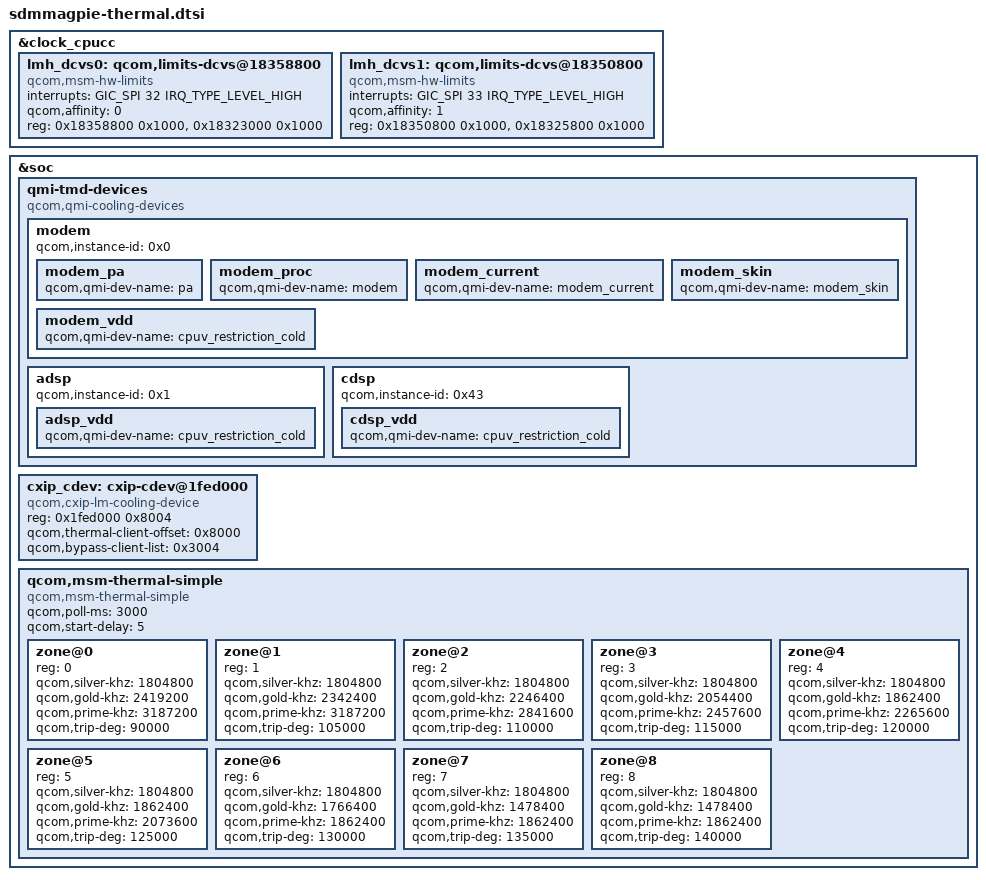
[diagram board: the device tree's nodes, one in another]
/*
 * Copyright (c) 2018-2019, The Linux Foundation. All rights reserved.
 *
 * This program is free software; you can redistribute it and/or modify
 * it under the terms of the GNU General Public License version 2 and
 * only version 2 as published by the Free Software Foundation.
 *
 * This program is distributed in the hope that it will be useful,
 * but WITHOUT ANY WARRANTY; without even the implied warranty of
 * MERCHANTABILITY or FITNESS FOR A PARTICULAR PURPOSE.  See the
 * GNU General Public License for more details.
 */

#include <dt-bindings/thermal/thermal.h>

&clock_cpucc {
	#address-cells = <1>;
	#size-cells = <1>;
	lmh_dcvs0: qcom,limits-dcvs@18358800 {
		compatible = "qcom,msm-hw-limits";
		interrupts = <GIC_SPI 32 IRQ_TYPE_LEVEL_HIGH>;
		qcom,affinity = <0>;
		reg = <0x18358800 0x1000>,
			<0x18323000 0x1000>;
		#thermal-sensor-cells = <0>;
	};

	lmh_dcvs1: qcom,limits-dcvs@18350800 {
		compatible = "qcom,msm-hw-limits";
		interrupts = <GIC_SPI 33 IRQ_TYPE_LEVEL_HIGH>;
		qcom,affinity = <1>;
		reg = <0x18350800 0x1000>,
			<0x18325800 0x1000>;
		#thermal-sensor-cells = <0>;
	};
};

&soc {
	qmi-tmd-devices {
		compatible = "qcom,qmi-cooling-devices";

		modem {
			qcom,instance-id = <0x0>;

			modem_pa: modem_pa {
				qcom,qmi-dev-name = "pa";
				#cooling-cells = <2>;
			};

			modem_proc: modem_proc {
				qcom,qmi-dev-name = "modem";
				#cooling-cells = <2>;
			};

			modem_current: modem_current {
				qcom,qmi-dev-name = "modem_current";
				#cooling-cells = <2>;
			};

			modem_skin: modem_skin {
				qcom,qmi-dev-name = "modem_skin";
				#cooling-cells = <2>;
			};

			modem_vdd: modem_vdd {
				qcom,qmi-dev-name = "cpuv_restriction_cold";
				#cooling-cells = <2>;
			};
		};

		adsp {
			qcom,instance-id = <0x1>;

			adsp_vdd: adsp_vdd {
				qcom,qmi-dev-name = "cpuv_restriction_cold";
				#cooling-cells = <2>;
			};
		};

		cdsp {
			qcom,instance-id = <0x43>;

			cdsp_vdd: cdsp_vdd {
				qcom,qmi-dev-name = "cpuv_restriction_cold";
				#cooling-cells = <2>;
			};
		};
	};

	cxip_cdev: cxip-cdev@1fed000 {
		compatible = "qcom,cxip-lm-cooling-device";
		reg = <0x1fed000 0x8004>;
		qcom,thermal-client-offset = <0x8000>;
		qcom,bypass-client-list = <0x3004>;
		#cooling-cells = <2>;
	};
};

// Simple MSM Thermal Solution for Alioth
&soc {
	qcom,msm-thermal-simple {
		compatible = "qcom,msm-thermal-simple";
		qcom,poll-ms = <3000>;
		qcom,start-delay = <5>;

		zone@0 {
			reg = <0>;
			qcom,silver-khz = <1804800>;
			qcom,gold-khz = <2419200>;
			qcom,prime-khz = <3187200>;
			qcom,trip-deg = <90000>;
		};

		zone@1 {
			reg = <1>;
			qcom,silver-khz = <1804800>;
			qcom,gold-khz = <2342400>;
			qcom,prime-khz = <3187200>;
			qcom,trip-deg = <105000>;
		};

		zone@2 {
			reg = <2>;
			qcom,silver-khz = <1804800>;
			qcom,gold-khz = <2246400>;
			qcom,prime-khz = <2841600>;
			qcom,trip-deg = <110000>;
		};

		zone@3 {
			reg = <3>;
			qcom,silver-khz = <1804800>;
			qcom,gold-khz = <2054400>;
			qcom,prime-khz = <2457600>;
			qcom,trip-deg = <115000>;
		};

		zone@4 {
			reg = <4>;
			qcom,silver-khz = <1804800>;
			qcom,gold-khz = <1862400>;
			qcom,prime-khz = <2265600>;
			qcom,trip-deg = <120000>;
		};

		zone@5 {
			reg = <5>;
			qcom,silver-khz = <1804800>;
			qcom,gold-khz = <1862400>;
			qcom,prime-khz = <2073600>;
			qcom,trip-deg = <125000>;
		};

		zone@6 {
			reg = <6>;
			qcom,silver-khz = <1804800>;
			qcom,gold-khz = <1766400>;
			qcom,prime-khz = <1862400>;
			qcom,trip-deg = <130000>;
		};

		zone@7 {
			reg = <7>;
			qcom,silver-khz = <1804800>;
			qcom,gold-khz = <1478400>;
			qcom,prime-khz = <1862400>;
			qcom,trip-deg = <135000>;
		};


		zone@8 {
			reg = <8>;
			qcom,silver-khz = <1804800>;
			qcom,gold-khz = <1478400>;
			qcom,prime-khz = <1862400>;
			qcom,trip-deg = <140000>;
		};
	};
};
